# GPU_CM_CORE register map
Vendor: Texas Instruments
Peripheral module from a debugger description file (folder omap5430_ES2_PUBLIC).
Registers are 32-bit, access per field, reset 0x3 unless marked. A register's access mark holds for its fields unless they carry their own. Offsets are as the file gives them; lines under a group give offsets from that group; [hi:lo] are bit positions; {n}, {i} and the like mark numbered series; 'fields as' and 'values as' point back to an identical list; <NAME> marks a mode.

## GPU_CM_CORE
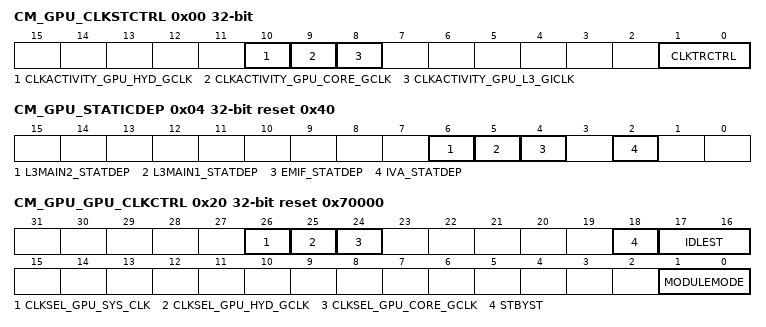
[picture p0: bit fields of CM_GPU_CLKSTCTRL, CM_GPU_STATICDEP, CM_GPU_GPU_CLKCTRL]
0x00 CM_GPU_CLKSTCTRL — This register enables the GPU domain power state transition. It controls the HW supervised domain power state transition between ON-ACTIVE and ON-INACTIVE states. It also holds 1 status bit per clock input of the domain.
  [10] CLKACTIVITY_GPU_HYD_GCLK ro — This field indicates the state of the GPU_HYD_GCLK clock in the domain. [warm reset insensitive]
    0=Inact (Corresponding clock is definitely gated); 1=Act (Corresponding clock is running or gating/ungating transition is on-going)
  [9] CLKACTIVITY_GPU_CORE_GCLK ro — This field indicates the state of the GPU_CORE_GCLK clock in the domain. [warm reset insensitive]
    values as CLKACTIVITY_GPU_HYD_GCLK
  [8] CLKACTIVITY_GPU_L3_GICLK ro — This field indicates the state of the GPU_L3_GICLK clock in the domain. [warm reset insensitive]
    0=Corresponding_clock_is_definitely_gated; 1=CLKACTIVITY_GPU_L3_GICLK_1_r (Corresponding clock is running or gating/ungating transition is on-going)
  [1:0] CLKTRCTRL rw — Controls the clock state transition of the GPU clock domain.
    0=NO_SLEEP (NO_SLEEP: Sleep transition cannot be initiated. Wakeup transition may however occur.); 1=SW_SLEEP (SW_SLEEP: Start a software forced sleep transition on the domain.); 2=SW_WKUP (SW_WKUP: Start a software forced wake-up transition on the domain.); 3=HW_AUTO (HW_AUTO: Automatic transition is enabled. Sleep and wakeup transition are based upon hardware conditions.)
0x04 CM_GPU_STATICDEP access not given reset 0x40 — This register controls the static domain depedencies from GPU domain towards 'target' domains. It is relevant only for domain having system initiator(s).
  [6] L3MAIN2_STATDEP — Static dependency towards L3_MAIN2 clock domain (access R Rreturns1s)
    1=Enabled (Dependency is enabled)
  [5] L3MAIN1_STATDEP rw — Static dependency towards L3_MAIN1 clock domain
    0=Disabled (Dependency is disabled); 1=Enabled (Dependency is enabled)
  [4] EMIF_STATDEP rw — Static dependency towards EMIF clock domain
    values as L3MAIN1_STATDEP
  [2] IVA_STATDEP rw — Static dependency towards IVA clock domain
    values as L3MAIN1_STATDEP
0x08 CM_GPU_DYNAMICDEP ro reset 0x0 — This register controls the dynamic domain depedencies from GPU domain towards 'target' domains. It is relevant only for domain having INTRCONN master port(s).
  [6] L3MAIN2_DYNDEP — Dynamic dependency towards L3_MAIN2 clock domain
    0=Disabled (Dependency is disabled)
0x20 CM_GPU_GPU_CLKCTRL reset 0x70000 — This register manages the GPU clocks.
  [26] CLKSEL_GPU_SYS_CLK rw — Select the ratio of GPU_L3_GICLK (SYS_CLK) to L3_ICLK
    0=GPU_L3_ICLK_(SYS_CLK)_L3_ICLK_0 (GPU_L3_ICLK (SYS_CLK) is divide by 1 of L3_ICLK); 1=GPU_L3_ICLK_(SYS_CLK)_L3_ICLK_1 (GPU_L3_ICLK (SYS_CLK) is divide by 2 of L3_ICLK)
  [25] CLKSEL_GPU_HYD_GCLK rw — Select the source of GPU_HYD_GCLK
    0=SEL_DPLL_CORE (Functional clock is sourced from DPLL_CORE HSDIVIDER); 1=SEL_DPLL_PER (Functional clock is sourced from DPLL_PER HSDIVIDER)
  [24] CLKSEL_GPU_CORE_GCLK rw — Select the source of GPU_CORE_GCLK
    values as CLKSEL_GPU_HYD_GCLK
  [18] STBYST ro — Module standby status. [warm reset insensitive]
    0=Func (Module is functional (not in standby)); 1=Standby (Module is in standby)
  [17:16] IDLEST ro — Module idle status. [warm reset insensitive]
    0=Func (Module is fully functional, including INTRCONN); 1=Trans (Module is performing transition: wakeup, or sleep, or sleep abortion); 2=Idle (Module is in Idle mode (only INTRCONN part). It is functional if using separate functional clock); 3=Disable (Module is disabled and cannot be accessed)
  [1:0] MODULEMODE rw — Control the way mandatory clocks are managed.
    0=DISABLED (Module is disable by SW. Any INTRCONN access to module results in an error, except if resulting from a module wakeup (asynchronous wakeup).); 2=ENABLE (Module is explicitly enabled. Interface clock (if not used for functions) may be gated according to the clock domain state. Functional clocks are guaranted to stay present. As long as in this configuration, power domain sleep transition cannot happen.)
